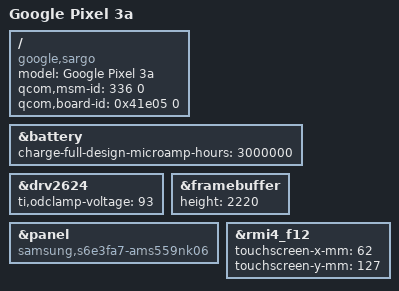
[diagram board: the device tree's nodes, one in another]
// SPDX-License-Identifier: GPL-2.0-only
/*
 * Device tree for Google Pixel 3a (non-XL).
 *
 * Copyright (c) Richard Acayan. All rights reserved.
 */

/dts-v1/;

#include "sdm670-google-common.dtsi"

/ {
	model = "Google Pixel 3a";
	compatible = "google,sargo", "google,b4s4-sdm670", "qcom,sdm670";
	/* ABL dtbo matching: SDM670 platform, S4 board, PVT revision */
	qcom,msm-id = <336 0>;
	qcom,board-id = <0x41e05 0>;
};

&battery {
	charge-full-design-microamp-hours = <3000000>;
};

&drv2624 {
	ti,odclamp-voltage = <93>; /* 1.8 Vrms */
};

&framebuffer {
	height = <2220>;
};

&panel {
	compatible = "samsung,s6e3fa7-ams559nk06";
};

&rmi4_f12 {
	touchscreen-x-mm = <62>;
	touchscreen-y-mm = <127>;
};
